# C64 register map
Vendor: Commodore Business Machines; Series: Commodore 64; File version: 0.1.0
CPU: other r0p0, little endian, no MPU, no FPU, 2 interrupt priority bits
Registers are 8-bit, read-write, no defined reset value unless marked. A register's access mark holds for its fields unless they carry their own. Offsets are from the block's base; [hi:lo] are bit positions; {n}, {i} and the like mark numbered series; 'fields as' and 'values as' point back to an identical list.

## VIC — VIC-II video interface (6567 NTSC / 6569 PAL) at 0xD000. Register image repeats every 0x40 bytes through 0xD3FF. Unimplemented bits read as 1. Addresses 0xD02F-0xD03F are not implemented on the 6567/6569: they read 0xFF and writes have no effect. Caveat: on a C128 in C64 mode, the VIC-IIe does implement 0xD02F (extended keyboard lines) and 0xD030 (2 MHz clock control) at these addresses. The VIC addresses 16 KiB selected by CIA2.CI2PRA bits 0-1. IRQ output drives the 6510 IRQ line.
Base 0x0000D000
{0x0+2i} SP{i}X (i=0..7) — Sprite X position bits 7:0 (bit 8 in MSIGX)
  [7:0] POSITION — Sprite X position, low 8 bits (bit 8 in MSIGX)
{0x1+2i} SP{i}Y (i=0..7) — Sprite Y position
  [7:0] POSITION
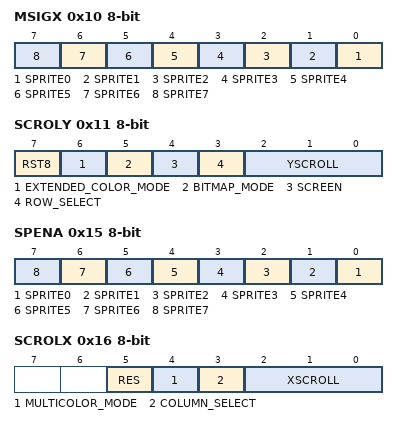
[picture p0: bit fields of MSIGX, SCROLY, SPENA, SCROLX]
0x10 MSIGX — Sprite X position bit 8; bit n belongs to sprite n
  [n] SPRITE{n} (n=0..7) — Sprite {n} X position bit 8
0x11 SCROLY — Control register 1. RST8 reads current raster bit 8, writes raster-compare bit 8.
  [7] RST8 — Raster bit 8 (read: current line; write: raster-IRQ compare)
  [6] EXTENDED_COLOR_MODE — Extended background color mode
    0=Disabled; 1=Enabled
  [5] BITMAP_MODE — Bitmap graphics mode
    0=Disabled; 1=Enabled
  [4] SCREEN — Enable the display; Disabled blanks the screen to border color
    0=Disabled; 1=Enabled
  [3] ROW_SELECT — Height of the display window - everything on screen that is not border. Rows25 spans raster 51-250, Rows24 only 55-246; switching to Rows24 mid-frame is how the top and bottom borders are opened. Fixes which YSCROLL the display needs - see YSCROLL. ([Bauer, The MOS 6567/6569 video controller (VIC-II)](https://www.cebix.net/VIC-Article.txt), 3.4 and 3.9.)
    0=Rows24; 1=Rows25
  [2:0] YSCROLL — Vertical fine scroll, and the Bad Line selector. A Bad Line is a raster line on which the VIC-II stalls the CPU to fetch the next row of screen and colour data; the first of each frame is raster 48 + YSCROLL, and that is the line character row 0 starts on. ROW_SELECT sets the first line of the display window - everything on screen that is not border - so only one YSCROLL puts row 0 on that line; the rest slide the character grid and clip the top row behind the border. That sliding is the scroll. ([Bauer, The MOS 6567/6569 video controller (VIC-II)](https://www.cebix.net/VIC-Article.txt), 3.4, 3.7 and 3.9.)
0x12 RASTER_R ro — Current raster line, bits 7:0 (bit 8 = SCROLY.RST8). Read-only view of 0xD012. Read and write are different registers at this address; the write view is RASTER_W, so neither exposes `.modify()`.
0x12 RASTER_W wo (alternate view of RASTER_R) — Raster line at which a raster IRQ fires (compare), bits 7:0 (bit 8 = SCROLY.RST8). Write-only alternate view of 0xD012; the current-line read view is RASTER_R.
  [7:0] RASTER_LINE — Raster line at which a raster IRQ fires, low 8 bits (bit 8 in SCROLY.RST8)
0x13 LPENX ro — Light pen X (2-pixel resolution)
0x14 LPENY ro — Light pen Y
0x15 SPENA — Sprite enable, bit n = sprite n
  [n] SPRITE{n} (n=0..7) — Sprite {n} enabled
    0=Disabled; 1=Enabled
0x16 SCROLX — Control register 2. Bits 6-7 unimplemented, read as 1.
  [5] RES — No function on 6567/6569
  [4] MULTICOLOR_MODE
    0=Disabled; 1=Enabled
  [3] COLUMN_SELECT — Text area width: 38 or 40 columns
    0=Col38; 1=Col40
  [2:0] XSCROLL — Horizontal fine scroll (0-7)
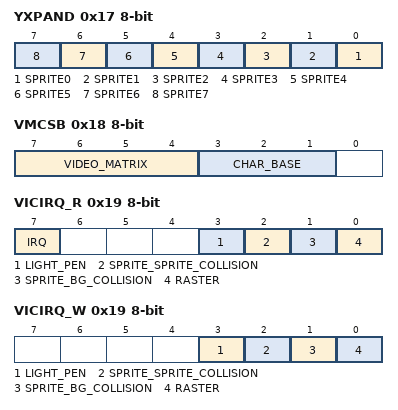
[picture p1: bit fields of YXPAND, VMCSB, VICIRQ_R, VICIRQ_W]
0x17 YXPAND — Sprite Y expansion, bit n = sprite n
  [n] SPRITE{n} (n=0..7) — Sprite {n} vertically expanded
    0=Disabled; 1=Enabled
0x18 VMCSB — Memory pointers within the current VIC bank. Bit 0 unimplemented.
  [7:4] VIDEO_MATRIX — Video matrix (screen) base, in 1 KiB steps from the base of the current VIC bank (register bits 7:4). [Mapping the C64](https://archive.org/details/Compute_s_Mapping_the_Commodore_64) quotes this as a whole-register value; divide the book value by 16 to get the field value, or use the named offsets below.
    0=OFFSET_0000 (Screen matrix at offset 0x0000 within the VIC bank); 1=OFFSET_0400 (Screen matrix at offset 0x0400 within the VIC bank); 2=OFFSET_0800 (Screen matrix at offset 0x0800 within the VIC bank); 3=OFFSET_0C00 (Screen matrix at offset 0x0C00 within the VIC bank); 4=OFFSET_1000 (Screen matrix at offset 0x1000 within the VIC bank); 5=OFFSET_1400 (Screen matrix at offset 0x1400 within the VIC bank); 6=OFFSET_1800 (Screen matrix at offset 0x1800 within the VIC bank); 7=OFFSET_1C00 (Screen matrix at offset 0x1C00 within the VIC bank); 8=OFFSET_2000 (Screen matrix at offset 0x2000 within the VIC bank); 9=OFFSET_2400 (Screen matrix at offset 0x2400 within the VIC bank); 10=OFFSET_2800 (Screen matrix at offset 0x2800 within the VIC bank); 11=OFFSET_2C00 (Screen matrix at offset 0x2C00 within the VIC bank); 12=OFFSET_3000 (Screen matrix at offset 0x3000 within the VIC bank); 13=OFFSET_3400 (Screen matrix at offset 0x3400 within the VIC bank); 14=OFFSET_3800 (Screen matrix at offset 0x3800 within the VIC bank); 15=OFFSET_3C00 (Screen matrix at offset 0x3C00 within the VIC bank)
  [3:1] CHAR_BASE — Character/bitmap base, in 2 KiB steps from the base of the current VIC bank (register bits 3:1). [Mapping the C64](https://archive.org/details/Compute_s_Mapping_the_Commodore_64) quotes this as a whole-register value; halve the book value to get the field value, or use the named offsets below.
    0=OFFSET_0000 (Character base at offset 0x0000 within the VIC bank); 1=OFFSET_0800 (Character base at offset 0x0800 within the VIC bank); 2=OFFSET_1000 (Character base at offset 0x1000 within the VIC bank - reads the character generator ROM, not RAM, in VIC banks 0 and 2); 3=OFFSET_1800 (Character base at offset 0x1800 within the VIC bank - reads the character generator ROM, not RAM, in VIC banks 0 and 2); 4=OFFSET_2000 (Character base at offset 0x2000 within the VIC bank); 5=OFFSET_2800 (Character base at offset 0x2800 within the VIC bank); 6=OFFSET_3000 (Character base at offset 0x3000 within the VIC bank); 7=OFFSET_3800 (Character base at offset 0x3800 within the VIC bank)
0x19 VICIRQ_R ro — Interrupt latch (read-only view of 0xD019): which VIC sources have fired. Bit 7 reads Latched while any enabled source is latched; bits 4-6 read as 1. Acknowledge via VICIRQ_W.
  [all] fields
    0=Inactive; 1=Latched
  [7] IRQ — Any enabled source latched
  [3] LIGHT_PEN
  [2] SPRITE_SPRITE_COLLISION
  [1] SPRITE_BG_COLLISION — Sprite-background collision
  [0] RASTER — Raster compare reached
0x19 VICIRQ_W wo write-1-clears (alternate view of VICIRQ_R) — Acknowledge latched VIC interrupts (write-only alternate view of 0xD019, write-1-to-clear). Writing Ack to a bit clears that source; Keep (0) leaves its flag pending. There is no read here - read status via VICIRQ_R. SIDE-EFFECT: an enabled source left un-acked re-asserts the IRQ immediately.
  [all] fields
    0=Keep; 1=Ack
  [3] LIGHT_PEN — Acknowledge light-pen interrupt
  [2] SPRITE_SPRITE_COLLISION — Acknowledge sprite-sprite collision interrupt
  [1] SPRITE_BG_COLLISION — Acknowledge sprite-background collision interrupt
  [0] RASTER — Acknowledge raster-compare interrupt
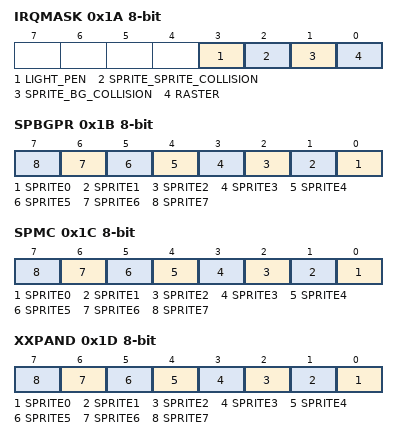
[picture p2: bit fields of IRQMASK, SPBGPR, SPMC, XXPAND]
0x1A IRQMASK — Interrupt enable for the four VICIRQ_R sources (same bit positions)
  [all] fields
    0=Disabled; 1=Enabled
  [3] LIGHT_PEN — Enable light pen interrupt
  [2] SPRITE_SPRITE_COLLISION — Enable sprite-sprite collision interrupt
  [1] SPRITE_BG_COLLISION — Enable sprite-background collision interrupt
  [0] RASTER — Enable raster interrupt
0x1B SPBGPR — Sprite-to-background priority, bit n = sprite n (1 = background in front)
  [n] SPRITE{n} (n=0..7) — Sprite {n} drawn behind background (1 = behind)
    0=InFront; 1=Behind
0x1C SPMC — Sprite multicolor enable, bit n = sprite n
  [n] SPRITE{n} (n=0..7) — Sprite {n} multicolor
    0=Disabled; 1=Enabled
0x1D XXPAND — Sprite X expansion, bit n = sprite n
  [n] SPRITE{n} (n=0..7) — Sprite {n} horizontally expanded
    0=Disabled; 1=Enabled
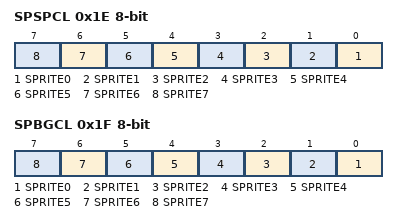
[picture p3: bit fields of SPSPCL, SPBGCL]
0x1E SPSPCL ro read-clears — Sprite-sprite collision latch. SIDE-EFFECT: reading clears the latch - read once and keep the value.
  [n] SPRITE{n} (n=0..7) — Sprite {n} collided with another sprite
    0=Clear; 1=Collided
0x1F SPBGCL ro read-clears — Sprite-background collision latch. SIDE-EFFECT: reading clears the latch - read once and keep the value.
  [n] SPRITE{n} (n=0..7) — Sprite {n} collided with the background
    0=Clear; 1=Collided
0x20 EXTCOL — Border color (bits 3:0; upper bits read as 1)
  [3:0] COLOR — Border color
    0=Black; 1=White; 2=Red; 3=Cyan; 4=Purple; 5=Green; 6=Blue; 7=Yellow; 8=Orange; 9=Brown; 10=LightRed; 11=DarkGray; 12=MediumGray; 13=LightGreen; 14=LightBlue; 15=LightGray
{0x21+i} BGCOL{i} (i=0..3) — Background color (bits 3:0)
  [3:0] COLOR — Background color
    values as EXTCOL.COLOR
0x25 SPMC0 — Sprite multicolor 0 (bits 3:0)
  [3:0] COLOR — Shared sprite multicolor 0
    values as EXTCOL.COLOR
0x26 SPMC1 — Sprite multicolor 1 (bits 3:0)
  [3:0] COLOR — Shared sprite multicolor 1
    values as EXTCOL.COLOR
{0x27+i} SP{i}COL (i=0..7) — Sprite color (bits 3:0)
  [3:0] COLOR — Sprite color
    values as EXTCOL.COLOR
